VERSION ""

NS_ :

BS_:

BU_:

BO_ 128 SYNC: 0 Vector__XXX

BO_ 0 NMT: 2 Vector__XXX
 SG_ MESSAGE : 8|8@1+ (1,0) [0|255] "" Vector__XXX
 SG_ DestinationNodeID : 0|8@1+ (1,0) [0|255] "" Vector__XXX

BO_ 1802 NMT_RESPONSE: 1 Vector__XXX
 SG_ MESSAGE : 0|8@1+ (1,0) [0|255] "" Vector__XXX

BO_ 2021 LSS_COMMAND: 8 Vector__XXX
 SG_ MODE : 8|8@1+ (1,0) [0|255] "" Vector__XXX
 SG_ COMMAND_SPECIFIER : 0|8@1+ (1,0) [0|255] "" Vector__XXX

BO_ 2020 LSS_RESPONSE: 8 Vector__XXX
 SG_ COMMAND_SPECIFIER : 0|8@1+ (1,0) [0|255] "" Vector__XXX

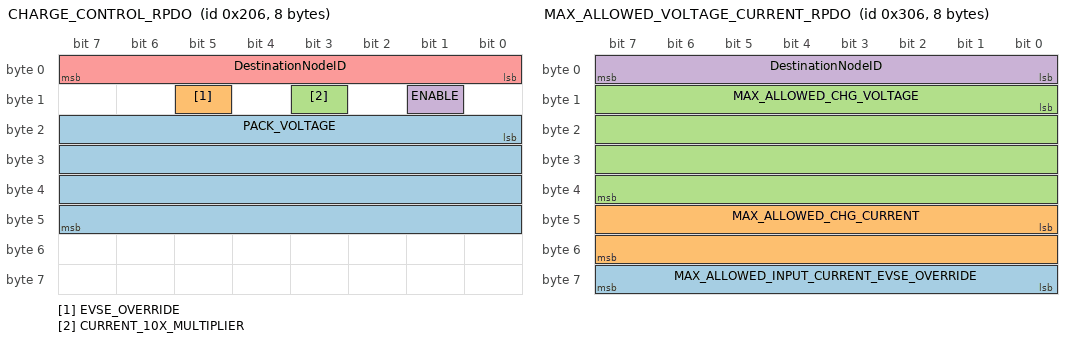
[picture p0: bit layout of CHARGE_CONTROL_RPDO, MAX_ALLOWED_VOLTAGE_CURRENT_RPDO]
BO_ 518 CHARGE_CONTROL_RPDO: 8 Vector__XXX
 SG_ PACK_VOLTAGE : 16|32@1+ (1,0) [0|4294967295] "mV" Vector__XXX
 SG_ EVSE_OVERRIDE : 13|1@1+ (1,0) [0|1] "" Vector__XXX
 SG_ CURRENT_10X_MULTIPLIER : 11|1@1+ (1,0) [0|1] "" Vector__XXX
 SG_ ENABLE : 9|1@1+ (1,0) [0|1] "" Vector__XXX
 SG_ DestinationNodeID : 0|8@1+ (1,0) [0|255] "" Vector__XXX

BO_ 774 MAX_ALLOWED_VOLTAGE_CURRENT_RPDO: 8 Vector__XXX
 SG_ MAX_ALLOWED_INPUT_CURRENT_EVSE_OVERRIDE : 56|8@1+ (1,0) [0|255] "A" Vector__XXX
 SG_ MAX_ALLOWED_CHG_CURRENT : 40|16@1+ (1,0) [0|65535] "mA" Vector__XXX
 SG_ MAX_ALLOWED_CHG_VOLTAGE : 8|32@1+ (1,0) [0|4.29497e+009] "mV" Vector__XXX
 SG_ DestinationNodeID : 0|8@1+ (1,0) [0|255] "" Vector__XXX

BO_ 1034 BMSA_RPDO_CONTROL: 8 Vector__XXX
 SG_ BMS_CNTRL_CONCT_ISO_CIR : 41|1@1+ (1,0) [0|1] "" Vector__XXX
 SG_ BMS_CNTRL_ALLOW_ISO_TST : 40|1@1+ (1,0) [0|1] "" Vector__XXX
 SG_ BMS_CNTRL_CHRGR_EN : 37|1@1+ (1,0) [0|1] "" Vector__XXX
 SG_ BMS_CNTRL_CHRGR_CON : 36|1@1+ (1,0) [0|1] "" Vector__XXX
 SG_ BMS_CNTRL_STRG_MODE_STRT : 34|1@1+ (1,0) [0|1] "" Vector__XXX
 SG_ BMS_CNTRL_LOCK : 33|1@1+ (1,0) [0|1] "" Vector__XXX
 SG_ BMS_CNTRL_SYS_ON : 32|1@1+ (1,0) [0|1] "" Vector__XXX
 SG_ BMS_CNTRL_MBB_FIRM_ID : 16|16@1+ (1,0) [0|65535] "" Vector__XXX
 SG_ BMS_CNTRL_DEST_NODE_ID : 0|8@1+ (1,0) [0|255] "" Vector__XXX
 SG_ BMS_CNTRL_UNUSED_BIT_1 : 35|1@1+ (1,0) [0|0] "" Vector__XXX
 SG_ BMS_CNTRL_UNUSED_BIT_2 : 38|1@1+ (1,0) [0|0] "" Vector__XXX
 SG_ BMS_CNTRL_UNUSED_BYTE_1 : 8|8@1+ (1,0) [0|0] "" Vector__XXX
 SG_ BMS_CNTRL_UNUSED_BIT_3 : 39|1@1+ (1,0) [0|0] "" Vector__XXX
 SG_ BMS_CNTRL_UNUSED_BIT_4 : 42|1@1+ (1,0) [0|0] "" Vector__XXX
 SG_ BMS_CNTRL_UNUSED_BIT_5 : 43|1@1+ (1,0) [0|0] "" Vector__XXX
 SG_ BMS_CNTRL_UNUSED_BIT_6 : 44|1@1+ (1,0) [0|0] "" Vector__XXX
 SG_ BMS_CNTRL_UNUSED_BIT_7 : 45|1@1+ (1,0) [0|0] "" Vector__XXX
 SG_ BMS_CNTRL_UNUSED_BIT_8 : 46|1@1+ (1,0) [0|0] "" Vector__XXX
 SG_ BMS_CNTRL_UNUSED_BIT_9 : 47|1@1+ (1,0) [0|0] "" Vector__XXX
 SG_ BMS_CNTRL_UNUSED_SHORT_1 : 48|16@1+ (1,0) [0|0] "" Vector__XXX

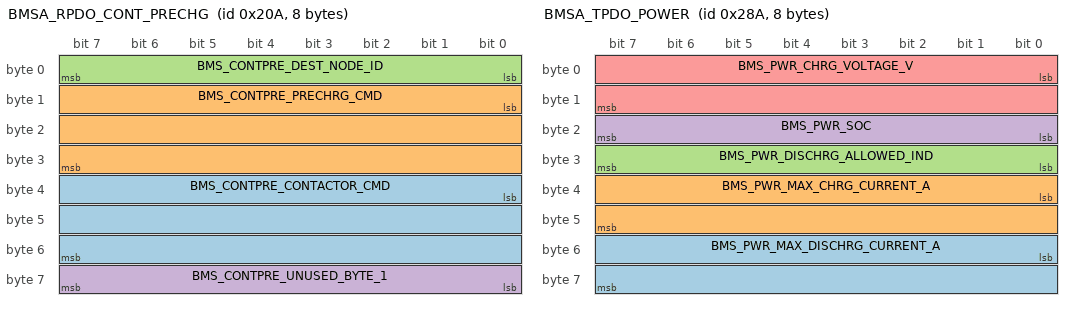
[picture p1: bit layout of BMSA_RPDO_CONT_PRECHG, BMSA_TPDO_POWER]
BO_ 522 BMSA_RPDO_CONT_PRECHG: 8 Vector__XXX
 SG_ BMS_CONTPRE_CONTACTOR_CMD : 32|24@1+ (1,0) [0|16777200] "" Vector__XXX
 SG_ BMS_CONTPRE_PRECHRG_CMD : 8|24@1+ (1,0) [0|16777200] "" Vector__XXX
 SG_ BMS_CONTPRE_DEST_NODE_ID : 0|8@1+ (1,0) [0|255] "" Vector__XXX
 SG_ BMS_CONTPRE_UNUSED_BYTE_1 : 56|8@1+ (1,0) [0|0] "" Vector__XXX

BO_ 394 BMSA_TPDO_STATUS: 8 BMSA
 SG_ BMS_STAT_CURRENT_MA : 32|24@1- (1,0) [-2147480000|2147480000] "" Vector__XXX
 SG_ BMS_STAT_FAULT_GENERAL : 27|1@1- (1,0) [0|1] "" Vector__XXX
 SG_ BMS_STAT_FAULT_TEMP_SENSOR : 26|1@1- (1,0) [0|1] "" Vector__XXX
 SG_ BMS_STAT_FAULT_CURRENT_SENSOR : 25|1@1- (1,0) [0|1] "" Vector__XXX
 SG_ BMS_STAT_FAULT_ISOLATION : 24|1@1- (1,0) [0|1] "" Vector__XXX
 SG_ BMS_STAT_FAULT_CHARGE : 23|1@1- (1,0) [0|1] "" Vector__XXX
 SG_ BMS_STAT_FAULT_DISCHARGE : 22|1@1- (1,0) [0|1] "" Vector__XXX
 SG_ BMS_STAT_FAULT_PRECHARGE : 21|1@1- (1,0) [0|1] "" Vector__XXX
 SG_ BMS_STAT_FAULT_CONTACTOR : 20|1@1- (1,0) [0|1] "" Vector__XXX
 SG_ BMS_STAT_BATT_V_LOW_CRIT : 18|1@1- (1,0) [0|1] "" Vector__XXX
 SG_ BMS_STAT_BATT_V_LOW : 17|1@1- (1,0) [0|1] "" Vector__XXX
 SG_ BMS_STAT_BATT_TEMP_CRIT : 16|1@1- (1,0) [0|1] "" Vector__XXX
 SG_ BMS_STAT_PCK_TEMP_LOW_CHRG : 15|1@1- (1,0) [0|1] "" Vector__XXX
 SG_ BMS_STAT_PCK_TEMP_HIGH_CHRG : 14|1@1- (1,0) [0|1] "" Vector__XXX
 SG_ BMS_STAT_PCK_TEMP_LOW_DISCHRG : 13|1@1- (1,0) [0|1] "" Vector__XXX
 SG_ BMS_STAT_PCK_TEMP_HIGH_DISCHRG : 12|1@1- (1,0) [0|1] "" Vector__XXX
 SG_ BMS_STAT_PACK_IMBALANCED : 10|1@1- (1,0) [0|1] "" Vector__XXX
 SG_ BMS_STAT_CELL_TOO_LOW_FOR_CHRG : 9|1@1- (1,0) [0|1] "" Vector__XXX
 SG_ BMS_STAT_CELL_TOO_HIGH_FOR_CHRG : 8|1@1- (1,0) [0|1] "" Vector__XXX
 SG_ BMS_STAT_FULL : 6|1@1- (1,0) [0|1] "" Vector__XXX
 SG_ BMS_STAT_CHARGE_EN : 5|1@1- (1,0) [0|1] "" Vector__XXX
 SG_ BMS_STAT_DISCHARGE_EN : 4|1@1- (1,0) [0|1] "" Vector__XXX
 SG_ BMS_STAT_PRECHARGE_OK : 2|1@1- (1,0) [0|1] "" Vector__XXX
 SG_ BMS_STAT_CONTACTOR_CLOSED : 1|1@1- (1,0) [0|1] "" Vector__XXX
 SG_ BMS_STAT_IDLE : 0|1@1- (1,0) [0|1] "" Vector__XXX
 SG_ BMS_STAT_FAULT_STATE : 28|1@1- (1,0) [0|1] "" Vector__XXX
 SG_ BMS_STAT_FAULT_ALERT : 29|1@1- (1,0) [0|1] "" Vector__XXX
 SG_ BMS_STAT_CHG_NEEDED : 3|1@1+ (1,0) [0|0] "" Vector__XXX
 SG_ BMS_STAT_STRG_MODE : 7|1@1+ (1,0) [0|0] "" Vector__XXX
 SG_ BMS_STAT_CELL_ANOM : 11|1@1+ (1,0) [0|0] "" Vector__XXX
 SG_ BMS_STAT_BATT_LVC : 19|1@1+ (1,0) [0|0] "" Vector__XXX
 SG_ BMS_STAT_FAULT_FUSE_TEMP : 30|1@1+ (1,0) [0|0] "" Vector__XXX
 SG_ BMS_STAT_VALID_ISO_RESULT : 31|1@1+ (1,0) [0|0] "" Vector__XXX
 SG_ BMS_STAT_STAT2_LPBP_LOW : 56|1@1+ (1,0) [0|0] "" Vector__XXX
 SG_ BMS_STAT_STAT2_UNUSED_BIT_1 : 57|1@1+ (1,0) [0|0] "" Vector__XXX
 SG_ BMS_STAT_STAT2_UNUSED_BIT_2 : 58|1@1+ (1,0) [0|0] "" Vector__XXX
 SG_ BMS_STAT_STAT2_UNUSED_BIT_3 : 59|1@1+ (1,0) [0|0] "" Vector__XXX
 SG_ BMS_STAT_STAT2_UNUSED_BIT_4 : 60|1@1+ (1,0) [0|0] "" Vector__XXX
 SG_ BMS_STAT_STAT2_UNUSED_BIT_5 : 61|1@1+ (1,0) [0|0] "" Vector__XXX
 SG_ BMS_STAT_STAT2_UNUSED_BIT_6 : 62|1@1+ (1,0) [0|0] "" Vector__XXX
 SG_ BMS_STAT_STAT2_UNUSED_BIT_7 : 63|1@1+ (1,0) [0|0] "" Vector__XXX

BO_ 650 BMSA_TPDO_POWER: 8 Vector__XXX
 SG_ BMS_PWR_MAX_DISCHRG_CURRENT_A : 48|16@1+ (1,0) [0|65535] "" Vector__XXX
 SG_ BMS_PWR_MAX_CHRG_CURRENT_A : 32|16@1+ (1,0) [0|65535] "" Vector__XXX
 SG_ BMS_PWR_DISCHRG_ALLOWED_IND : 24|8@1+ (1,0) [0|255] "" Vector__XXX
 SG_ BMS_PWR_SOC : 16|8@1+ (1,0) [0|255] "" Vector__XXX
 SG_ BMS_PWR_CHRG_VOLTAGE_V : 0|16@1+ (1,0) [0|65535] "" Vector__XXX

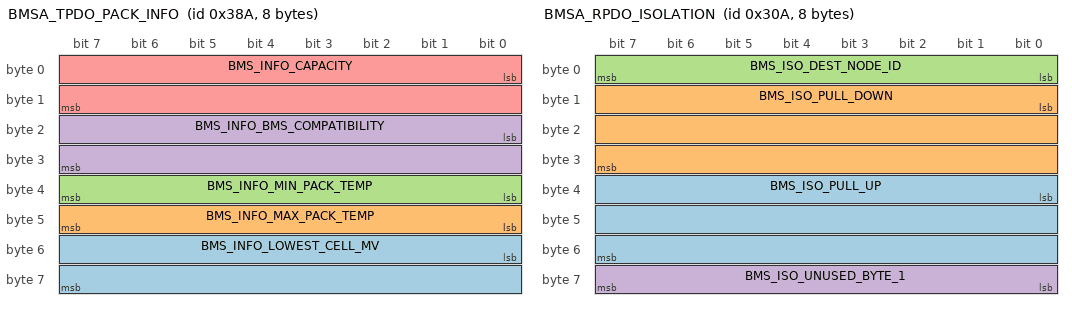
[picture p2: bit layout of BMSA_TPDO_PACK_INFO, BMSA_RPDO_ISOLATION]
BO_ 906 BMSA_TPDO_PACK_INFO: 8 Vector__XXX
 SG_ BMS_INFO_LOWEST_CELL_MV : 48|16@1+ (1,0) [0|65535] "" Vector__XXX
 SG_ BMS_INFO_MAX_PACK_TEMP : 40|8@1- (1,0) [-128|127] "" Vector__XXX
 SG_ BMS_INFO_MIN_PACK_TEMP : 32|8@1- (1,0) [-128|127] "" Vector__XXX
 SG_ BMS_INFO_BMS_COMPATIBILITY : 16|16@1+ (1,0) [0|65535] "" Vector__XXX
 SG_ BMS_INFO_CAPACITY : 0|16@1+ (1,0) [0|65535] "" Vector__XXX

BO_ 1162 BMSA_TPDO_VOLTAGE: 8 Vector__XXX
 SG_ BMS_VOLT_PACK_VOLTAGE_OC : 32|32@1+ (1,0) [0|-1] "" Vector__XXX
 SG_ BMS_VOLT_PACK_VOLTAGE_RAW : 0|32@1+ (1,0) [0|-1] "" Vector__XXX

BO_ 778 BMSA_RPDO_ISOLATION: 8 Vector__XXX
 SG_ BMS_ISO_PULL_UP : 32|24@1+ (1,0) [0|16777200] "" Vector__XXX
 SG_ BMS_ISO_PULL_DOWN : 8|24@1+ (1,0) [0|16777200] "" Vector__XXX
 SG_ BMS_ISO_DEST_NODE_ID : 0|8@1+ (1,0) [0|255] "" Vector__XXX
 SG_ BMS_ISO_UNUSED_BYTE_1 : 56|8@1+ (1,0) [0|0] "" Vector__XXX

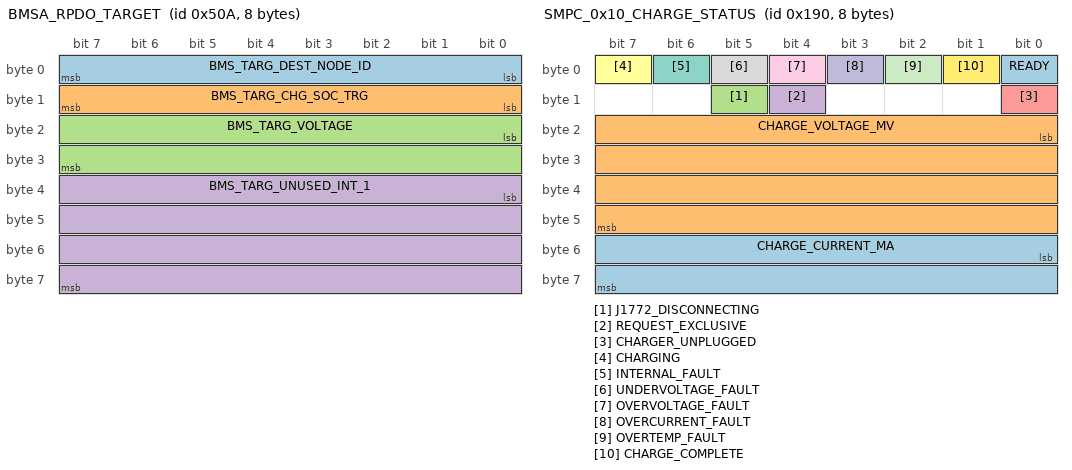
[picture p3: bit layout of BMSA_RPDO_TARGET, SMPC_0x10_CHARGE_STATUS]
BO_ 1290 BMSA_RPDO_TARGET: 8 Vector__XXX
 SG_ BMS_TARG_DEST_NODE_ID : 0|8@1+ (1,0) [0|0] "" Vector__XXX
 SG_ BMS_TARG_CHG_SOC_TRG : 8|8@1+ (1,0) [0|0] "" Vector__XXX
 SG_ BMS_TARG_VOLTAGE : 16|16@1+ (1,0) [0|0] "" Vector__XXX
 SG_ BMS_TARG_UNUSED_INT_1 : 32|32@1+ (1,0) [0|0] "" Vector__XXX

BO_ 400 SMPC_0x10_CHARGE_STATUS: 8 Vector__XXX
 SG_ CHARGE_CURRENT_MA : 48|16@1+ (1,0) [0|65535] "mA" Vector__XXX
 SG_ CHARGE_VOLTAGE_MV : 16|32@1+ (1,0) [0|4294970000] "mV" Vector__XXX
 SG_ J1772_DISCONNECTING : 13|1@1- (1,0) [0|1] "" Vector__XXX
 SG_ REQUEST_EXCLUSIVE : 12|1@1- (1,0) [0|1] "" Vector__XXX
 SG_ CHARGER_UNPLUGGED : 8|1@1- (1,0) [0|1] "" Vector__XXX
 SG_ CHARGING : 7|1@1- (1,0) [0|1] "" Vector__XXX
 SG_ INTERNAL_FAULT : 6|1@1- (1,0) [0|1] "" Vector__XXX
 SG_ UNDERVOLTAGE_FAULT : 5|1@1- (1,0) [0|1] "" Vector__XXX
 SG_ OVERVOLTAGE_FAULT : 4|1@1- (1,0) [0|1] "" Vector__XXX
 SG_ OVERCURRENT_FAULT : 3|1@1- (1,0) [0|1] "" Vector__XXX
 SG_ OVERTEMP_FAULT : 2|1@1- (1,0) [0|1] "" Vector__XXX
 SG_ CHARGE_COMPLETE : 1|1@1- (1,0) [0|1] "" Vector__XXX
 SG_ READY : 0|1@1- (1,0) [0|1] "" Vector__XXX

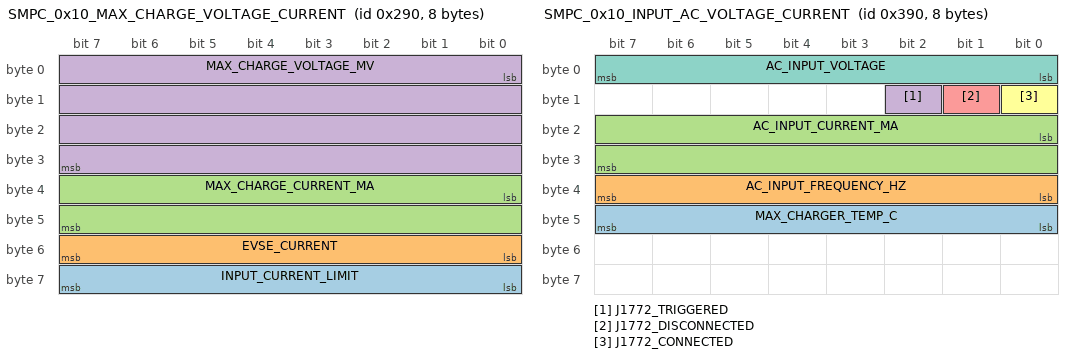
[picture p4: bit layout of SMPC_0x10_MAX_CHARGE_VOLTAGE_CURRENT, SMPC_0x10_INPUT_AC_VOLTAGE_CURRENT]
BO_ 656 SMPC_0x10_MAX_CHARGE_VOLTAGE_CURRENT: 8 Vector__XXX
 SG_ INPUT_CURRENT_LIMIT : 56|8@1+ (1,0) [0|255] "A" Vector__XXX
 SG_ EVSE_CURRENT : 48|8@1+ (1,0) [0|255] "A" Vector__XXX
 SG_ MAX_CHARGE_CURRENT_MA : 32|16@1+ (1,0) [0|65535] "mA" Vector__XXX
 SG_ MAX_CHARGE_VOLTAGE_MV : 0|32@1+ (1,0) [0|4294970000] "mV" Vector__XXX

BO_ 912 SMPC_0x10_INPUT_AC_VOLTAGE_CURRENT: 8 Vector__XXX
 SG_ MAX_CHARGER_TEMP_C : 40|8@1+ (1,-50) [-50|205] "C" Vector__XXX
 SG_ AC_INPUT_FREQUENCY_HZ : 32|8@1+ (1,0) [0|255] "HZ" Vector__XXX
 SG_ AC_INPUT_CURRENT_MA : 16|16@1+ (1,0) [0|65535] "mA" Vector__XXX
 SG_ J1772_TRIGGERED : 10|1@1- (1,0) [0|1] "" Vector__XXX
 SG_ J1772_DISCONNECTED : 9|1@1- (1,0) [0|1] "" Vector__XXX
 SG_ J1772_CONNECTED : 8|1@1- (1,0) [0|1] "" Vector__XXX
 SG_ AC_INPUT_VOLTAGE : 0|8@1+ (1,0) [0|255] "Vac" Vector__XXX

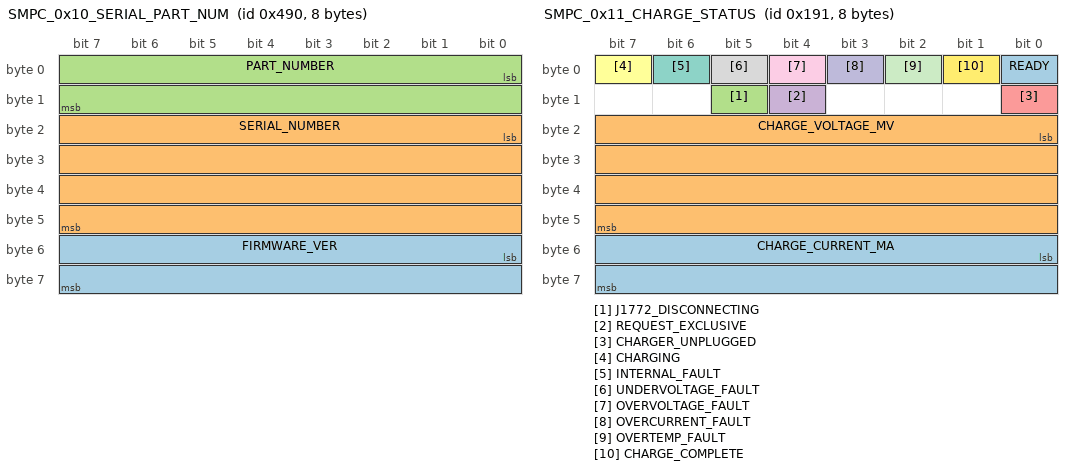
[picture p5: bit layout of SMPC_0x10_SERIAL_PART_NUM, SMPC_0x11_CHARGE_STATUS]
BO_ 1168 SMPC_0x10_SERIAL_PART_NUM: 8 Vector__XXX
 SG_ FIRMWARE_VER : 48|16@1+ (1,0) [0|65535] "" Vector__XXX
 SG_ SERIAL_NUMBER : 16|32@1+ (1,0) [0|4294970000] "" Vector__XXX
 SG_ PART_NUMBER : 0|16@1+ (1,0) [0|65535] "" Vector__XXX

BO_ 401 SMPC_0x11_CHARGE_STATUS: 8 Vector__XXX
 SG_ CHARGE_CURRENT_MA : 48|16@1+ (1,0) [0|65535] "mA" Vector__XXX
 SG_ CHARGE_VOLTAGE_MV : 16|32@1+ (1,0) [0|4294970000] "mV" Vector__XXX
 SG_ J1772_DISCONNECTING : 13|1@1- (1,0) [0|1] "" Vector__XXX
 SG_ REQUEST_EXCLUSIVE : 12|1@1- (1,0) [0|1] "" Vector__XXX
 SG_ CHARGER_UNPLUGGED : 8|1@1- (1,0) [0|1] "" Vector__XXX
 SG_ CHARGING : 7|1@1- (1,0) [0|1] "" Vector__XXX
 SG_ INTERNAL_FAULT : 6|1@1- (1,0) [0|1] "" Vector__XXX
 SG_ UNDERVOLTAGE_FAULT : 5|1@1- (1,0) [0|1] "" Vector__XXX
 SG_ OVERVOLTAGE_FAULT : 4|1@1- (1,0) [0|1] "" Vector__XXX
 SG_ OVERCURRENT_FAULT : 3|1@1- (1,0) [0|1] "" Vector__XXX
 SG_ OVERTEMP_FAULT : 2|1@1- (1,0) [0|1] "" Vector__XXX
 SG_ CHARGE_COMPLETE : 1|1@1- (1,0) [0|1] "" Vector__XXX
 SG_ READY : 0|1@1- (1,0) [0|1] "" Vector__XXX

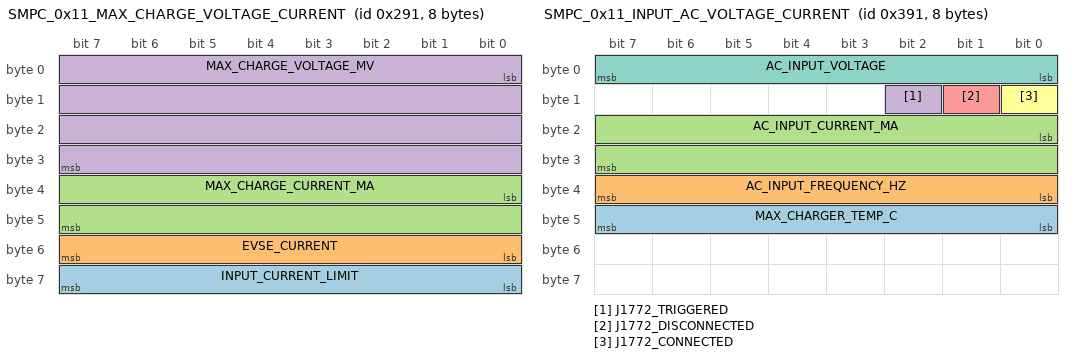
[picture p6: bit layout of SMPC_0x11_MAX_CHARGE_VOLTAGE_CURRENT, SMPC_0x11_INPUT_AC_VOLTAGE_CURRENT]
BO_ 657 SMPC_0x11_MAX_CHARGE_VOLTAGE_CURRENT: 8 Vector__XXX
 SG_ INPUT_CURRENT_LIMIT : 56|8@1+ (1,0) [0|255] "A" Vector__XXX
 SG_ EVSE_CURRENT : 48|8@1+ (1,0) [0|255] "A" Vector__XXX
 SG_ MAX_CHARGE_CURRENT_MA : 32|16@1+ (1,0) [0|65535] "mA" Vector__XXX
 SG_ MAX_CHARGE_VOLTAGE_MV : 0|32@1+ (1,0) [0|4294970000] "mV" Vector__XXX

BO_ 913 SMPC_0x11_INPUT_AC_VOLTAGE_CURRENT: 8 Vector__XXX
 SG_ MAX_CHARGER_TEMP_C : 40|8@1+ (1,-50) [-50|205] "C" Vector__XXX
 SG_ AC_INPUT_FREQUENCY_HZ : 32|8@1+ (1,0) [0|255] "HZ" Vector__XXX
 SG_ AC_INPUT_CURRENT_MA : 16|16@1+ (1,0) [0|65535] "mA" Vector__XXX
 SG_ J1772_TRIGGERED : 10|1@1- (1,0) [0|1] "" Vector__XXX
 SG_ J1772_DISCONNECTED : 9|1@1- (1,0) [0|1] "" Vector__XXX
 SG_ J1772_CONNECTED : 8|1@1- (1,0) [0|1] "" Vector__XXX
 SG_ AC_INPUT_VOLTAGE : 0|8@1+ (1,0) [0|255] "Vac" Vector__XXX

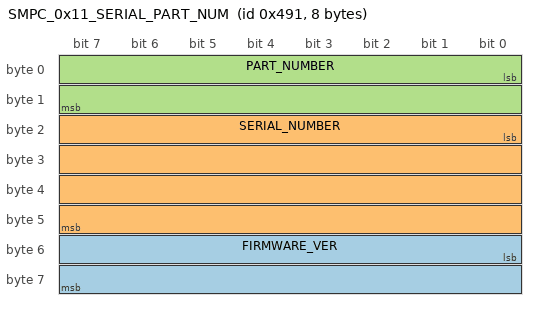
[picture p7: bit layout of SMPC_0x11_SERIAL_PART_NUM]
BO_ 1169 SMPC_0x11_SERIAL_PART_NUM: 8 Vector__XXX
 SG_ FIRMWARE_VER : 48|16@1+ (1,0) [0|65535] "" Vector__XXX
 SG_ SERIAL_NUMBER : 16|32@1+ (1,0) [0|4294970000] "" Vector__XXX
 SG_ PART_NUMBER : 0|16@1+ (1,0) [0|65535] "" Vector__XXX

BO_ 1810 IGNORE: 1 Vector__XXX
 SG_ NA : 0|8@1+ (1,0) [0|255] "" Vector__XXX

BO_ 144 IGNORE_0: 8 Vector__XXX
 SG_ NA : 0|8@1+ (1,0) [0|255] "" Vector__XXX

BO_ 1542 IGNORE_1: 8 Vector__XXX
 SG_ NA : 0|8@1+ (1,0) [0|255] "" Vector__XXX

BO_ 1 ERR: 0 Vector__XXX
